# PIC16F1619 register map
File version: 1.0
Registers are 8-bit, read-write, reset 0x0 unless marked. A register's access mark holds for its fields unless they carry their own. Offsets are from the block's base; [hi:lo] are bit positions; {n}, {i} and the like mark numbered series.

## OSCILLATOR
Base 0x00800098
0x00 OSCTUNE — OSCTUNE, data address 0x098
  [5:0] TUN
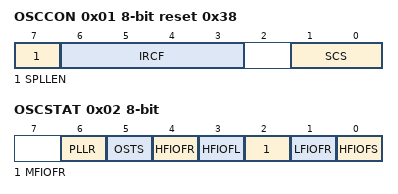
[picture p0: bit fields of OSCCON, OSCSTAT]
0x01 OSCCON reset 0x38 — OSCCON, data address 0x099
  [7] SPLLEN, [6:3] IRCF, [1:0] SCS
0x02 OSCSTAT (reset mask 0x5B) — OSCSTAT, data address 0x09a
  [6] PLLR, [5] OSTS, [4] HFIOFR, [3] HFIOFL, [2] MFIOFR, [1] LFIOFR, [0] HFIOFS

## PORTA
Base 0x0080000C
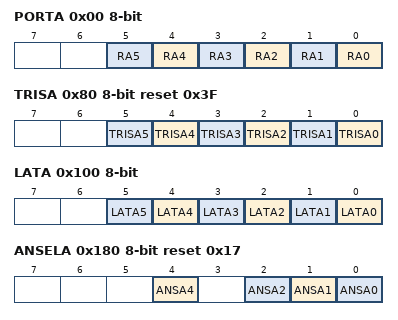
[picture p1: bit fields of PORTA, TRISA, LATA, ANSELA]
0x00 PORTA reset not defined — PORTA, data address 0x00c
  [n] RA{n} (n=0..5)
0x80 TRISA reset 0x3F — TRISA, data address 0x08c
  [n] TRISA{n} (n=0..5)
0x100 LATA reset not defined — LATA, data address 0x10c
  [n] LATA{n} (n=0..5)
0x180 ANSELA reset 0x17 — ANSELA, data address 0x18c
  [4] ANSA4, [2] ANSA2, [1] ANSA1, [0] ANSA0
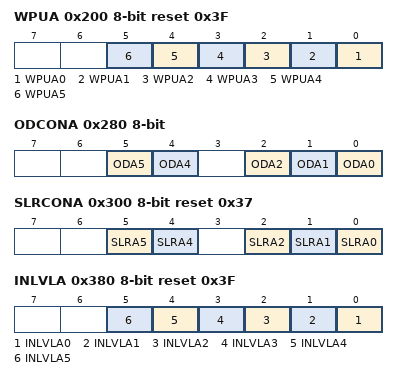
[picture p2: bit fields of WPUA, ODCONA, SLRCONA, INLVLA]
0x200 WPUA reset 0x3F — WPUA, data address 0x20c
  [n] WPUA{n} (n=0..5)
0x280 ODCONA — ODCONA, data address 0x28c
  [5] ODA5, [4] ODA4, [2] ODA2, [1] ODA1, [0] ODA0
0x300 SLRCONA reset 0x37 — SLRCONA, data address 0x30c
  [5] SLRA5, [4] SLRA4, [2] SLRA2, [1] SLRA1, [0] SLRA0
0x380 INLVLA reset 0x3F — INLVLA, data address 0x38c
  [n] INLVLA{n} (n=0..5)
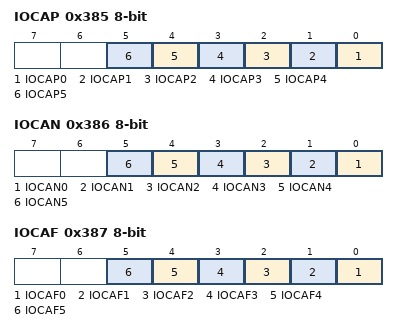
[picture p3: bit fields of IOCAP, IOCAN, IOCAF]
0x385 IOCAP — IOCAP, data address 0x391
  [n] IOCAP{n} (n=0..5)
0x386 IOCAN — IOCAN, data address 0x392
  [n] IOCAN{n} (n=0..5)
0x387 IOCAF — IOCAF, data address 0x393
  [n] IOCAF{n} (n=0..5)

## PORTB
Base 0x0080000D
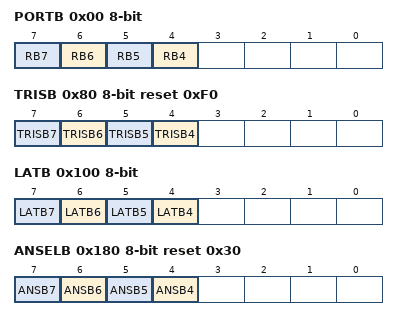
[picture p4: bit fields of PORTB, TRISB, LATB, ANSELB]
0x00 PORTB reset not defined — PORTB, data address 0x00d
  [n] RB{n} (n=4..7)
0x80 TRISB reset 0xF0 — TRISB, data address 0x08d
  [n] TRISB{n} (n=4..7)
0x100 LATB reset not defined — LATB, data address 0x10d
  [n] LATB{n} (n=4..7)
0x180 ANSELB reset 0x30 (reset mask 0x30) — ANSELB, data address 0x18d
  [n] ANSB{n} (n=4..7)
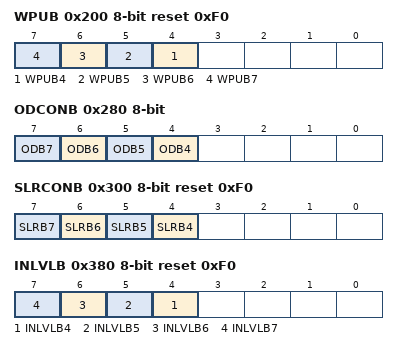
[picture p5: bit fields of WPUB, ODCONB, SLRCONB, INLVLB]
0x200 WPUB reset 0xF0 — WPUB, data address 0x20d
  [n] WPUB{n} (n=4..7)
0x280 ODCONB — ODCONB, data address 0x28d
  [n] ODB{n} (n=4..7)
0x300 SLRCONB reset 0xF0 — SLRCONB, data address 0x30d
  [n] SLRB{n} (n=4..7)
0x380 INLVLB reset 0xF0 — INLVLB, data address 0x38d
  [n] INLVLB{n} (n=4..7)
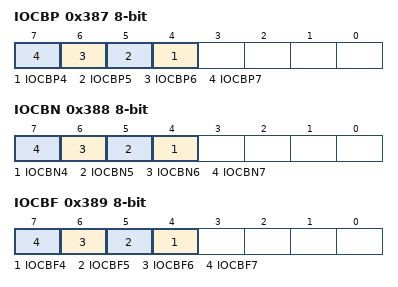
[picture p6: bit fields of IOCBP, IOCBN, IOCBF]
0x387 IOCBP — IOCBP, data address 0x394
  [n] IOCBP{n} (n=4..7)
0x388 IOCBN — IOCBN, data address 0x395
  [n] IOCBN{n} (n=4..7)
0x389 IOCBF — IOCBF, data address 0x396
  [n] IOCBF{n} (n=4..7)

## PORTC
Base 0x0080000E
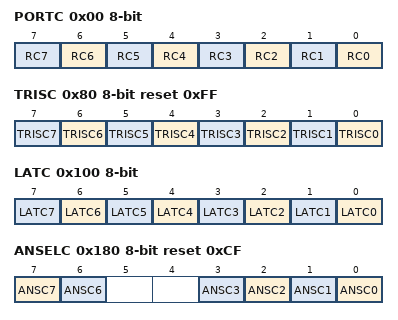
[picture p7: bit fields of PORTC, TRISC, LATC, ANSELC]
0x00 PORTC reset not defined — PORTC, data address 0x00e
  [n] RC{n} (n=0..7)
0x80 TRISC reset 0xFF — TRISC, data address 0x08e
  [n] TRISC{n} (n=0..7)
0x100 LATC reset not defined — LATC, data address 0x10e
  [n] LATC{n} (n=0..7)
0x180 ANSELC reset 0xCF — ANSELC, data address 0x18e
  [7] ANSC7, [6] ANSC6, [n] ANSC{n} (n=0..3)
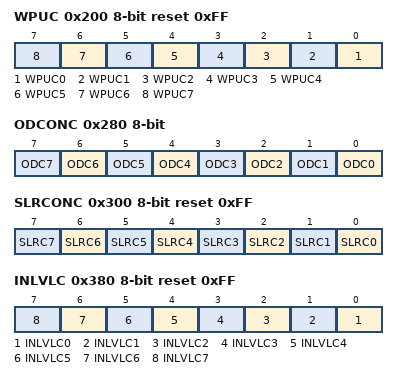
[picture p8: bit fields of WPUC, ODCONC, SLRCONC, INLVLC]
0x200 WPUC reset 0xFF — WPUC, data address 0x20e
  [n] WPUC{n} (n=0..7)
0x280 ODCONC — ODCONC, data address 0x28e
  [n] ODC{n} (n=0..7)
0x300 SLRCONC reset 0xFF — SLRCONC, data address 0x30e
  [n] SLRC{n} (n=0..7)
0x380 INLVLC reset 0xFF — INLVLC, data address 0x38e
  [n] INLVLC{n} (n=0..7)
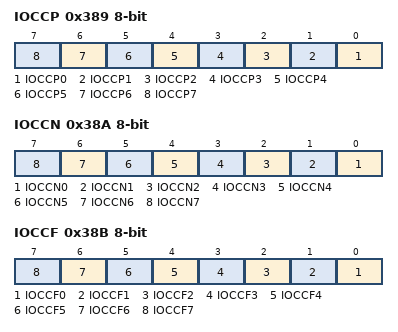
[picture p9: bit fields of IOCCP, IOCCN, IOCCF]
0x389 IOCCP — IOCCP, data address 0x397
  [n] IOCCP{n} (n=0..7)
0x38A IOCCN — IOCCN, data address 0x398
  [n] IOCCN{n} (n=0..7)
0x38B IOCCF — IOCCF, data address 0x399
  [n] IOCCF{n} (n=0..7)

## PPS — Peripheral pin select
Base 0x00800E0F
0x00 PPSLOCK — PPSLOCK, data address 0xe0f
  [0] PPSLOCKED
0x01 INTPPS reset 0x2 — INTPPS, data address 0xe10
  [4:0] INTPPS
0x02 T0CKIPPS reset 0x2 — T0CKIPPS, data address 0xe11
  [4:0] T0CKIPPS
0x03 T1CKIPPS reset 0x5 — T1CKIPPS, data address 0xe12
  [4:0] T1CKIPPS
0x04 T1GPPS reset 0x4 — T1GPPS, data address 0xe13
  [4:0] T1GPPS
0x07 ATINPPS reset 0x15 — ATINPPS, data address 0xe16
  [4:0] ATINPPS
0x08 CWG1INPPS reset 0x2 — CWG1INPPS, data address 0xe17
  [4:0] CWG1INPPS
0x09 T2CKIPPS reset 0x5 — T2CKIPPS, data address 0xe18
  [4:0] T2CKIPPS
0x0A T3CKIPPS reset 0x15 — T3CKIPPS, data address 0xe19
  [4:0] T3CKIPPS
0x0B T3GPPS reset 0x14 — T3GPPS, data address 0xe1a
  [4:0] T3GPPS
0x0C T4CKIPPS reset 0x11 — T4CKIPPS, data address 0xe1b
  [4:0] T4CKIPPS
0x0D T5CKIPPS reset 0x10 — T5CKIPPS, data address 0xe1c
  [4:0] T5CKIPPS
0x0E T5GPPS reset 0x13 — T5GPPS, data address 0xe1d
  [4:0] T5GPPS
0x0F T6CKIPPS reset 0x3 — T6CKIPPS, data address 0xe1e
  [4:0] T6CKIPPS
0x10 ATCC1PPS reset 0x13 — ATCC1PPS, data address 0xe1f
  [4:0] ATCC1PPS
0x14 ATCC2PPS reset 0x14 — ATCC2PPS, data address 0xe23
  [4:0] ATCC2PPS
0x15 RXPPS reset 0xD — RXPPS, data address 0xe24
  [4:0] RXPPS
0x16 CKPPS reset 0xF — CKPPS, data address 0xe25
  [4:0] CKPPS
0x17 SMT1SIGPPS reset 0x4 — SMT1SIGPPS, data address 0xe26
  [4:0] SMT1SIGPPS
0x18 SMT1WINPPS reset 0x5 — SMT1WINPPS, data address 0xe27
  [4:0] SMT1WINPPS
0x19 CLCIN0PPS reset 0x13 — CLCIN0PPS, data address 0xe28
  [4:0] CLCN0PPS
0x1A CLCIN1PPS reset 0x14 — CLCIN1PPS, data address 0xe29
  [4:0] CLCIN1PPS
0x1B CLCIN2PPS reset 0x11 — CLCIN2PPS, data address 0xe2a
  [4:0] CLCIN2PPS
0x1C CLCIN3PPS reset 0x5 — CLCIN3PPS, data address 0xe2b
  [4:0] CLCIN3PPS
0x1D SMT2SIGPPS reset 0x11 — SMT2SIGPPS, data address 0xe2c
  [4:0] SMT2SIGPPS
0x1E SMT2WINPPS reset 0x3 — SMT2WINPPS, data address 0xe2d
  [4:0] SMT2WINPPS
0x1F ATCC3PPS reset 0x15 — ATCC3PPS, data address 0xe2e
  [4:0] ATCC3PPS
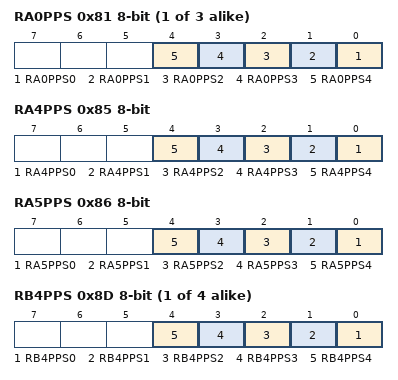
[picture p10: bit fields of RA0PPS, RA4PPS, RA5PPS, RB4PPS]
{0x81+i} RA{i}PPS (i=0..2) — RA{i}PPS, data address {0xE90+i}
  [n] RA{i}PPS{n} (n=0..4)
0x85 RA4PPS — RA4PPS, data address 0xe94
  [n] RA4PPS{n} (n=0..4)
0x86 RA5PPS — RA5PPS, data address 0xe95
  [n] RA5PPS{n} (n=0..4)
{0x89+i} RB{i}PPS (i=4..7) — RB{i}PPS, data address {0xE98+i}
  [n] RB{i}PPS{n} (n=0..4)
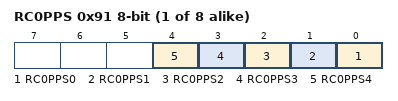
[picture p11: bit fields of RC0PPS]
{0x91+i} RC{i}PPS (i=0..7) — RC{i}PPS, data address {0xEA0+i}
  [n] RC{i}PPS{n} (n=0..4)

## REFERENCES — Voltage reference, DAC and SR latch
Base 0x00800117
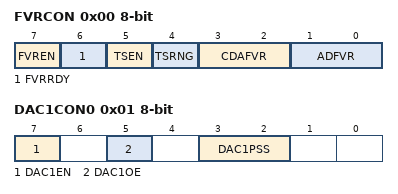
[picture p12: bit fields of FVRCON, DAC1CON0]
0x00 FVRCON (reset mask 0xB3) — FVRCON, data address 0x117
  [7] FVREN, [6] FVRRDY, [5] TSEN, [4] TSRNG, [3:2] CDAFVR, [1:0] ADFVR
0x01 DAC1CON0 — DAC1CON0, data address 0x118
  [7] DAC1EN, [5] DAC1OE, [3:2] DAC1PSS
0x02 DAC1CON1 — DAC1CON1, data address 0x119
  [7:0] DAC1R

## SYSTEM — Reset, watchdog and pin options
Base 0x00800095
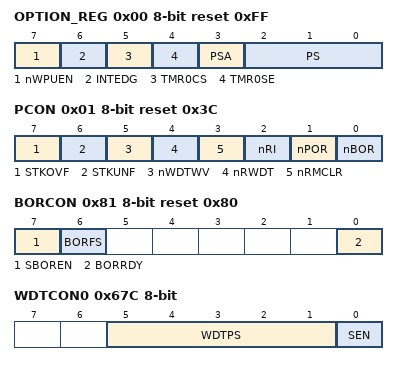
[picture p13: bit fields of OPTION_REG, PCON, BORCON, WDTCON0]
0x00 OPTION_REG reset 0xFF — OPTION_REG, data address 0x095
  [7] nWPUEN, [6] INTEDG, [5] TMR0CS, [4] TMR0SE, [3] PSA, [2:0] PS
0x01 PCON reset 0x3C (reset mask 0xFC) — PCON, data address 0x096
  [7] STKOVF, [6] STKUNF, [5] nWDTWV, [4] nRWDT, [3] nRMCLR, [2] nRI, [1] nPOR, [0] nBOR
0x81 BORCON reset 0x80 (reset mask 0xC0) — BORCON, data address 0x116
  [7] SBOREN, [6] BORFS, [0] BORRDY
0x102 VREGCON reset 0x1 — VREGCON, data address 0x197
  [1:0] VREGPM
0x67C WDTCON0 (reset mask 0x1) — WDTCON0, data address 0x711
  [5:1] WDTPS, [0] SEN
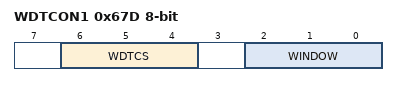
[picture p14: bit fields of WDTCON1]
0x67D WDTCON1 reset not defined — WDTCON1, data address 0x712
  [6:4] WDTCS, [2:0] WINDOW

## TIMER0
Base 0x00800015
0x00 TMR0 reset not defined — TMR0, data address 0x015

## TIMER1
Base 0x00800016
0x00 TMR1L reset not defined — TMR1L, data address 0x016
0x01 TMR1H reset not defined — TMR1H, data address 0x017
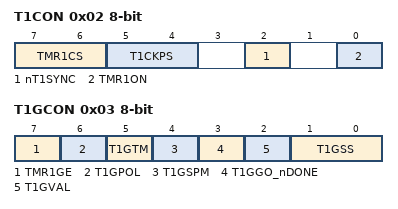
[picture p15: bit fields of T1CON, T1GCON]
0x02 T1CON — T1CON, data address 0x018
  [7:6] TMR1CS, [5:4] T1CKPS, [2] nT1SYNC, [0] TMR1ON
0x03 T1GCON (reset mask 0xFB) — T1GCON, data address 0x019
  [7] TMR1GE, [6] T1GPOL, [5] T1GTM, [4] T1GSPM, [3] T1GGO_nDONE, [2] T1GVAL, [1:0] T1GSS

## TIMER2
Base 0x0080001C
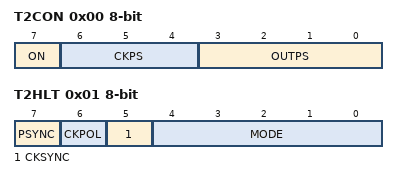
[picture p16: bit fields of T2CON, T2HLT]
0x00 T2CON — T2CON, data address 0x01c
  [7] ON, [6:4] CKPS, [3:0] OUTPS
0x01 T2HLT — T2HLT, data address 0x01d
  [7] PSYNC, [6] CKPOL, [5] CKSYNC, [4:0] MODE
0x02 T2CLKCON — T2CLKCON, data address 0x01e
  [3:0] CS
0x03 T2RST — T2RST, data address 0x01f
  [3:0] RSEL

## TIMER3
Base 0x00800493
0x00 TMR3L reset not defined — TMR3L, data address 0x493
0x01 TMR3H reset not defined — TMR3H, data address 0x494
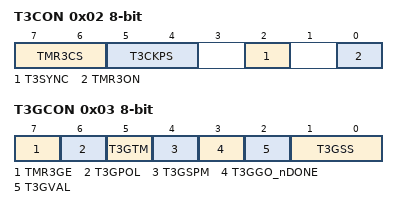
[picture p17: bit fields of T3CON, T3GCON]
0x02 T3CON reset not defined — T3CON, data address 0x495
  [7:6] TMR3CS, [5:4] T3CKPS, [2] T3SYNC, [0] TMR3ON
0x03 T3GCON reset not defined — T3GCON, data address 0x496
  [7] TMR3GE, [6] T3GPOL, [5] T3GTM, [4] T3GSPM, [3] T3GGO_nDONE, [2] T3GVAL, [1:0] T3GSS

## TIMER4
Base 0x00800415
0x00 T4CON — T4CON, data address 0x415
  [7] ON, [6:4] CKPS, [3:0] OUTPS
0x01 T4HLT — T4HLT, data address 0x416
  [7] PSYNC, [6] CKPOL, [5] CKSYNC, [4:0] MODE
0x02 T4CLKCON — T4CLKCON, data address 0x417
  [3:0] CS
0x03 T4RST — T4RST, data address 0x418
  [3:0] RSEL

## TIMER5
Base 0x0080049A
0x00 TMR5L reset not defined — TMR5L, data address 0x49a
0x01 TMR5H reset not defined — TMR5H, data address 0x49b
0x02 T5CON reset not defined — T5CON, data address 0x49c
  [7:6] TMR5CS, [5:4] T5CKPS, [2] T5SYNC, [0] TMR5ON
0x03 T5GCON reset not defined — T5GCON, data address 0x49d
  [7] TMR5GE, [6] T5GPOL, [5] T5GTM, [4] T5GSPM, [3] T5GGO_nDONE, [2] T5GVAL, [1:0] T5GSS

## TIMER6
Base 0x0080041C
0x00 T6CON — T6CON, data address 0x41c
  [7] ON, [6:4] CKPS, [3:0] OUTPS
0x01 T6HLT — T6HLT, data address 0x41d
  [7] PSYNC, [6] CKPOL, [5] CKSYNC, [4:0] MODE
0x02 T6CLKCON — T6CLKCON, data address 0x41e
  [3:0] CS
0x03 T6RST — T6RST, data address 0x41f
  [3:0] RSEL
